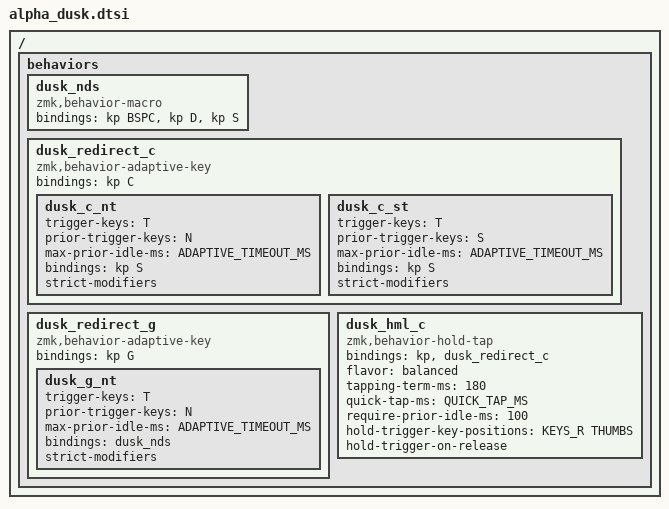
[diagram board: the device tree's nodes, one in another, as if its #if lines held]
/* Dusk — left-thumb alpha (r), right-thumb space. */

/* >>> generated adaptive swaps (do not edit — run ./scripts/generate) >>> */
#include "../generated/alpha_dusk.dtsi"
/* <<< end generated adaptive swaps <<< */

/*
 * Contextual redirects (hand-written; 2-key history / macro output, not swaps).
 *   ntc -> nts, stc -> sts : C outputs S when preceded by "nt"/"st".
 *   ntg -> nds : G deletes the prior T and emits "ds" when preceded by "nt".
 * Requires the extended zmk-adaptive-key fork (prior-trigger-keys).
 */
#if DUSK_ADAPTIVE
ZMK_MACRO(dusk_nds, bindings = <&kp BSPC &kp D &kp S>;)

ZMK_ADAPTIVE_KEY(dusk_redirect_c, bindings = <&kp C>;
    dusk_c_nt { trigger-keys = <T>; prior-trigger-keys = <N>; max-prior-idle-ms = <ADAPTIVE_TIMEOUT_MS>; bindings = <&kp S>; strict-modifiers; };
    dusk_c_st { trigger-keys = <T>; prior-trigger-keys = <S>; max-prior-idle-ms = <ADAPTIVE_TIMEOUT_MS>; bindings = <&kp S>; strict-modifiers; };
)
ZMK_ADAPTIVE_KEY(dusk_redirect_g, bindings = <&kp G>;
    dusk_g_nt { trigger-keys = <T>; prior-trigger-keys = <N>; max-prior-idle-ms = <ADAPTIVE_TIMEOUT_MS>; bindings = <&dusk_nds>; strict-modifiers; };
)
ZMK_HOLD_TAP(dusk_hml_c, bindings = <&kp>, <&dusk_redirect_c>;
             flavor = "balanced"; tapping-term-ms = <180>;
             quick-tap-ms = <QUICK_TAP_MS>; require-prior-idle-ms = <100>;
             hold-trigger-key-positions = <KEYS_R THUMBS>;
             hold-trigger-on-release;)
#define DUSK_C &dusk_hml_c LSHFT 0
#define DUSK_G &dusk_redirect_g
#endif

#ifndef DUSK_C
#define DUSK_C &hml LSHFT C
#endif
#ifndef DUSK_E
#define DUSK_E &hmr RALT E
#endif
#ifndef DUSK_G
#define DUSK_G &kp G
#endif
#ifndef DUSK_L
#define DUSK_L &kp L
#endif
#ifndef DUSK_M
#define DUSK_M &kp M
#endif
#ifndef DUSK_O
#define DUSK_O &kp O
#endif
#ifndef DUSK_U
#define DUSK_U &kp U
#endif

ZMK_BASE_LAYER(Dusk,
//╭──────────┬──────────┬──────────┬──────────┬──────────╮   ╭──────────┬──────────┬──────────┬──────────┬──────────╮
    &kp B      &kp F      &kp D      &kp W      &kp P      ,  &kp J      &sqt_dqt   DUSK_O     DUSK_U     &comma_excl ,
//├──────────┼──────────┼──────────┼──────────┼──────────┤   ├──────────┼──────────┼──────────┼──────────┼──────────┤
   &hml LGUI N &hml LALT S &hml LCTRL T DUSK_C &kp Y ,  DUSK_M     &hmr RSHFT H &hmr RCTRL A DUSK_E &hmr RGUI I ,
//├──────────┼──────────┼──────────┼──────────┼──────────┤   ├──────────┼──────────┼──────────┼──────────┼──────────┤
    &kp X      &kp V      &kp K      DUSK_G     &kp Q      ,  &kp Z      DUSK_L     &kp SEMI   &minus_slash &dot_qmark ,
//╰──────────┴──────────┴──────────┼──────────┼──────────┤   ├──────────┼──────────┼──────────┴──────────┴──────────╯
        LH_NONE &thumb_bspc LAYER_Nav 0  &thumb_spc LAYER_Mouse R , &thumb_spc LAYER_Symbol SPACE  &num_repeat LAYER_Num 0 RH_NONE
//                                 ╰──────────┴──────────╯   ╰──────────┴──────────╯
)
